VERSION ""

NS_ :

BS_:

BU_: JETSON VCU ACU RES DYN_F DYN_R FSG_DATA_LOGGER MAXON

BO_ 3221225472 VECTOR__INDEPENDENT_SIG_MSG: 0 Vector__XXX
 SG_ EBS_Pressure_Rear : 32|8@1+ (10,0) [0|150] "bar" Vector__XXX
 SG_ EBS_Pressure_Front : 24|8@1+ (10,0) [0|150] "bar" Vector__XXX
 SG_ NewSignal_0005 : 0|8@1+ (1,0) [0|0] "" Vector__XXX
 SG_ NewSignal_0015 : 32|8@1+ (1,0) [0|0] "" Vector__XXX
 SG_ NewSignal_0012 : 56|8@1+ (1,0) [0|0] "" Vector__XXX

BO_ 81 ACU_MS: 1 ACU
 SG_ Mission_Select : 0|8@1+ (1,0) [0|0] ""  JETSON

BO_ 97 JETSON_MS: 1 JETSON
 SG_ Mission_Select : 0|8@1+ (1,0) [0|0] ""  ACU

BO_ 1289 VCU_RPM: 2 VCU
 SG_ rpm_actual : 0|16@1- (1,0) [0|6000] "RPM"  JETSON

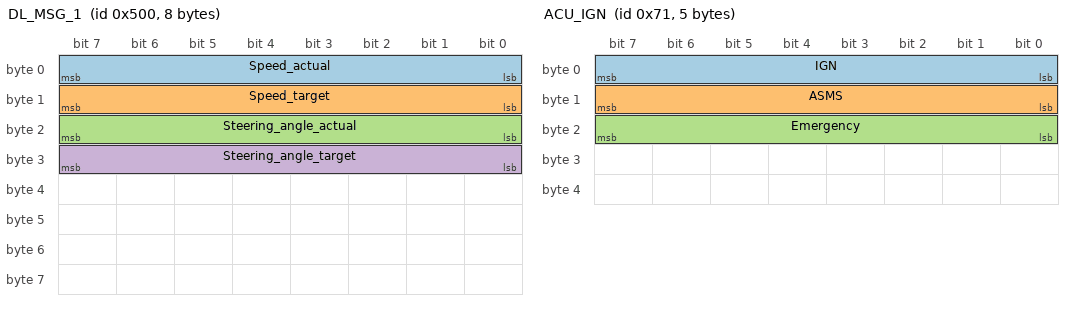
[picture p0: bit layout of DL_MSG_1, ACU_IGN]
BO_ 1280 DL_MSG_1: 8 ACU
 SG_ Speed_actual : 0|8@1+ (0.5,0) [0|0] "Km/h"  VCU
 SG_ Speed_target : 8|8@1+ (0.5,0) [0|0] "Km/h" Vector__XXX
 SG_ Steering_angle_actual : 16|8@1- (0.5,0) [0|0] "º" Vector__XXX
 SG_ Steering_angle_target : 24|8@1- (0.5,0) [0|0] "º" Vector__XXX

BO_ 113 ACU_IGN: 5 ACU
 SG_ IGN : 0|8@1+ (1,0) [0|1] ""  VCU
 SG_ ASMS : 8|8@1+ (1,0) [0|1] ""  VCU
 SG_ Emergency : 16|8@1+ (1,0) [0|0] ""  VCU

BO_ 1299 RD_JETSON: 1 ACU
 SG_ RD : 0|8@1+ (1,0) [0|0] ""  JETSON

BO_ 1283 AS_STATE: 1 JETSON
 SG_ STATE : 0|8@1+ (1,0) [0|0] ""  VCU,ACU

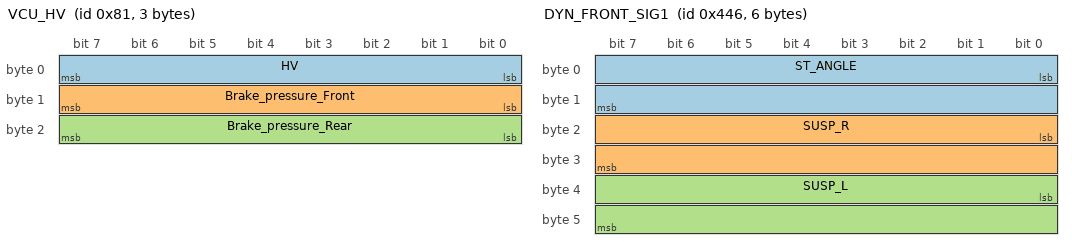
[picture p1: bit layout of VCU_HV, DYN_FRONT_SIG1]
BO_ 129 VCU_HV: 3 VCU
 SG_ HV : 0|8@1+ (1,0) [0|0] ""  ACU
 SG_ Brake_pressure_Front : 8|8@1+ (1,0) [0|0] "" Vector__XXX
 SG_ Brake_pressure_Rear : 16|8@1+ (1,0) [0|0] "" Vector__XXX

BO_ 401 RES: 8 RES
 SG_ SIGNAL : 0|8@1+ (1,0) [0|0] ""  JETSON,ACU

BO_ 1094 DYN_FRONT_SIG1: 6 DYN_F
 SG_ ST_ANGLE : 0|16@1- (0.1,0) [0|0] "º" Vector__XXX
 SG_ SUSP_R : 16|16@1+ (0.1,0) [0|0] "mm" Vector__XXX
 SG_ SUSP_L : 32|16@1+ (0.1,0) [0|0] "mm" Vector__XXX

BO_ 1110 DYN_FRONT_SIG2: 4 DYN_F
 SG_ SPD_LEFT : 0|16@1+ (0.1,0) [0|0] "km/h" Vector__XXX
 SG_ SPD_RIGHT : 16|16@1+ (0.1,0) [0|0] "km/h" Vector__XXX

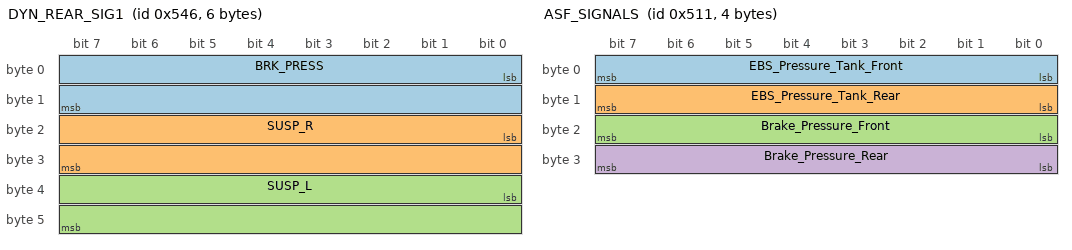
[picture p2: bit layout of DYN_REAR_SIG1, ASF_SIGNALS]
BO_ 1350 DYN_REAR_SIG1: 6 DYN_R
 SG_ BRK_PRESS : 0|16@1+ (0.1,0) [0|0] "bar" Vector__XXX
 SG_ SUSP_R : 16|16@1+ (0.1,0) [0|0] "mm" Vector__XXX
 SG_ SUSP_L : 32|16@1+ (0.1,0) [0|0] "mm" Vector__XXX

BO_ 1366 DYN_REAR_SIG2: 4 DYN_R
 SG_ SPD_LEFT : 0|16@1+ (0.1,0) [0|0] "km/h" Vector__XXX
 SG_ SPD_RIGHT : 16|16@1+ (0.1,0) [0|0] "km/h" Vector__XXX

BO_ 1297 ASF_SIGNALS: 4 ACU
 SG_ EBS_Pressure_Tank_Front : 0|8@1+ (10,0) [0|0] "bar" Vector__XXX
 SG_ EBS_Pressure_Tank_Rear : 8|8@1+ (10,0) [0|0] "bar" Vector__XXX
 SG_ Brake_Pressure_Front : 16|8@1+ (10,0) [0|0] "bar" Vector__XXX
 SG_ Brake_Pressure_Rear : 24|8@1+ (10,0) [0|0] "bar" Vector__XXX

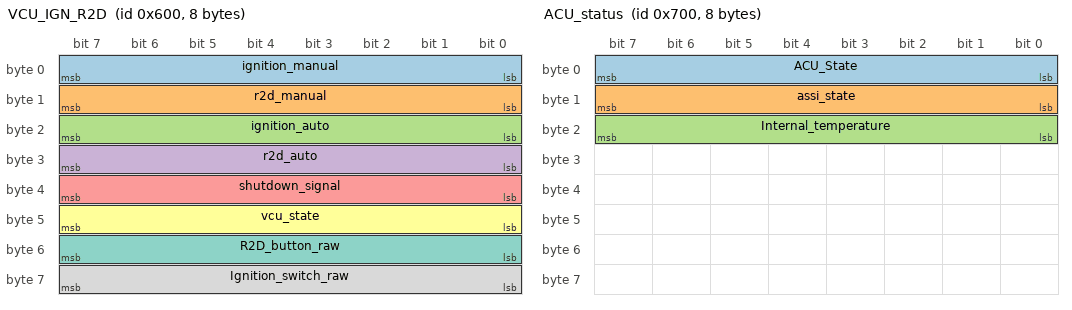
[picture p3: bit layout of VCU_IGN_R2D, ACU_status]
BO_ 1536 VCU_IGN_R2D: 8 VCU
 SG_ ignition_manual : 0|8@1+ (1,0) [0|0] "" Vector__XXX
 SG_ r2d_manual : 8|8@1+ (1,0) [0|0] "" Vector__XXX
 SG_ ignition_auto : 16|8@1+ (1,0) [0|0] "" Vector__XXX
 SG_ r2d_auto : 24|8@1+ (1,0) [0|0] "" Vector__XXX
 SG_ shutdown_signal : 32|8@1+ (1,0) [0|0] "" Vector__XXX
 SG_ vcu_state : 40|8@1+ (1,0) [0|0] "" Vector__XXX
 SG_ R2D_button_raw : 48|8@1+ (1,0) [0|0] "" Vector__XXX
 SG_ Ignition_switch_raw : 56|8@1+ (1,0) [0|0] "" Vector__XXX

BO_ 1792 ACU_status: 8 ACU
 SG_ ACU_State : 0|8@1+ (1,0) [0|0] "" Vector__XXX
 SG_ assi_state : 8|8@1+ (1,0) [0|0] "" Vector__XXX
 SG_ Internal_temperature : 16|8@1+ (1,0) [0|0] "º" Vector__XXX

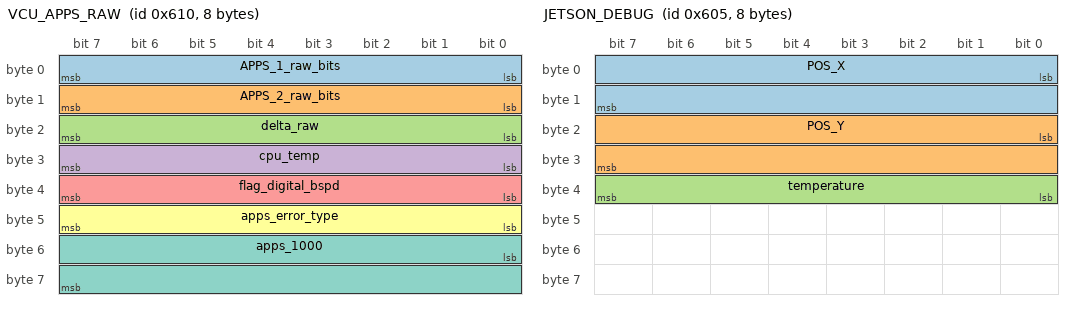
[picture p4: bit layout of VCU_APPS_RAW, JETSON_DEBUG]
BO_ 1552 VCU_APPS_RAW: 8 VCU
 SG_ APPS_1_raw_bits : 0|8@1+ (1,0) [0|0] "" Vector__XXX
 SG_ APPS_2_raw_bits : 8|8@1+ (1,0) [0|0] "" Vector__XXX
 SG_ delta_raw : 16|8@1+ (1,0) [0|0] "" Vector__XXX
 SG_ cpu_temp : 24|8@1+ (1,0) [0|0] "" Vector__XXX
 SG_ flag_digital_bspd : 32|8@1+ (1,0) [0|0] "" Vector__XXX
 SG_ apps_error_type : 40|8@1+ (1,0) [0|0] "" Vector__XXX
 SG_ apps_1000 : 48|16@1+ (1,0) [0|0] "" Vector__XXX

BO_ 1177 RPM_TARGET: 8 JETSON
 SG_ rpm_target : 0|16@1+ (1,0) [0|0] "" Vector__XXX

BO_ 1541 JETSON_DEBUG: 8 JETSON
 SG_ POS_X : 0|16@1+ (0.1,0) [0|0] "m" Vector__XXX
 SG_ POS_Y : 16|16@1+ (0.1,0) [0|0] "m" Vector__XXX
 SG_ temperature : 32|8@1+ (1,0) [0|0] "ºC" Vector__XXX

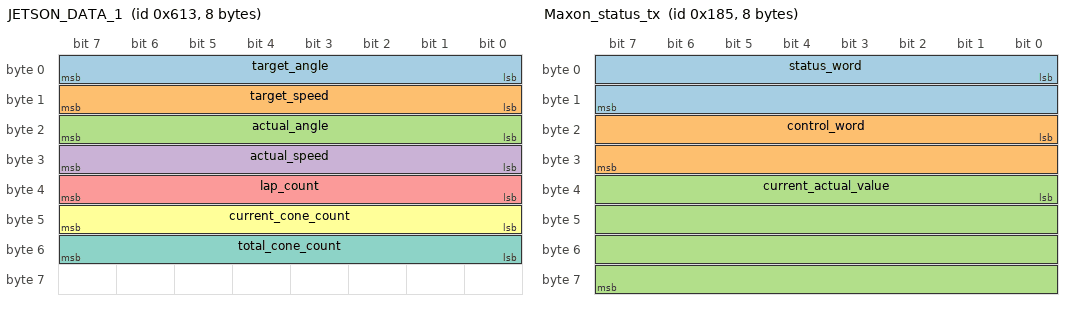
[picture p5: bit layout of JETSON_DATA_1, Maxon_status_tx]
BO_ 1555 JETSON_DATA_1: 8 JETSON
 SG_ target_angle : 0|8@1+ (0.5,0) [0|0] "º" Vector__XXX
 SG_ target_speed : 8|8@1+ (1,0) [0|0] "km/h" Vector__XXX
 SG_ actual_angle : 16|8@1+ (0.5,0) [0|0] "º" Vector__XXX
 SG_ actual_speed : 24|8@1+ (1,0) [0|0] "km/h" Vector__XXX
 SG_ lap_count : 32|8@1+ (1,0) [0|0] "" Vector__XXX
 SG_ current_cone_count : 40|8@1+ (1,0) [0|0] "" Vector__XXX
 SG_ total_cone_count : 48|8@1+ (1,0) [0|0] "" Vector__XXX

BO_ 517 Maxon_mode_rx: 2 MAXON
 SG_ Control_word : 0|8@1+ (1,0) [0|0] "" Vector__XXX

BO_ 1029 Maxon_position_rx: 6 MAXON
 SG_ control_word : 0|8@1+ (1,0) [0|0] "" Vector__XXX
 SG_ target_position : 16|32@1+ (1,0) [0|0] "" Vector__XXX

BO_ 773 Maxon_profile_rx: 8 MAXON
 SG_ profile_velocity : 0|32@1+ (1,0) [0|0] "" Vector__XXX
 SG_ profile_acceleration : 32|32@1+ (1,0) [0|0] "" Vector__XXX

BO_ 389 Maxon_status_tx: 8 MAXON
 SG_ status_word : 0|16@1+ (1,0) [0|0] "" Vector__XXX
 SG_ control_word : 16|16@1+ (1,0) [0|0] "" Vector__XXX
 SG_ current_actual_value : 32|32@1+ (1,0) [0|0] "" Vector__XXX

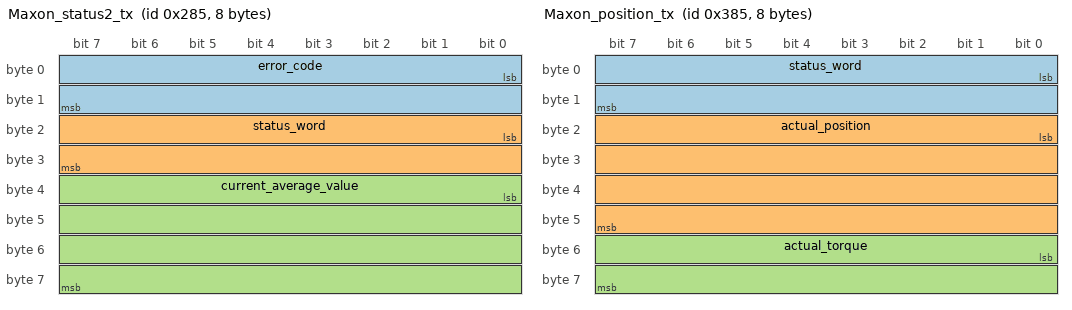
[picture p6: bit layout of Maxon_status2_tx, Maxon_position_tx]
BO_ 645 Maxon_status2_tx: 8 MAXON
 SG_ error_code : 0|16@1+ (1,0) [0|0] "" Vector__XXX
 SG_ status_word : 16|16@1+ (1,0) [0|0] "" Vector__XXX
 SG_ current_average_value : 32|32@1+ (1,0) [0|0] "" Vector__XXX

BO_ 901 Maxon_position_tx: 8 MAXON
 SG_ status_word : 0|16@1+ (1,0) [0|0] "" Vector__XXX
 SG_ actual_position : 16|32@1+ (1,0) [0|0] "" Vector__XXX
 SG_ actual_torque : 48|16@1+ (1,0) [0|0] "" Vector__XXX

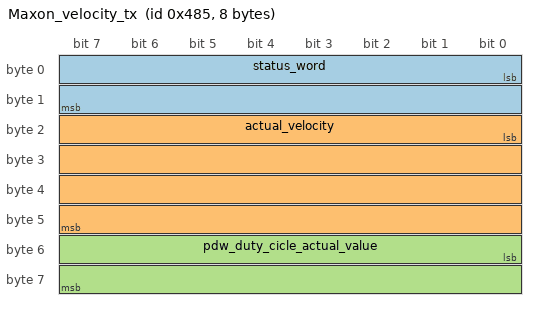
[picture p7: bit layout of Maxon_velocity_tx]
BO_ 1157 Maxon_velocity_tx: 8 MAXON
 SG_ status_word : 0|16@1+ (1,0) [0|0] "" Vector__XXX
 SG_ actual_velocity : 16|32@1+ (1,0) [0|0] "" Vector__XXX
 SG_ pdw_duty_cicle_actual_value : 48|16@1+ (1,0) [0|0] "" Vector__XXX

CM_ SG_ 3221225472 EBS_Pressure_Rear "(null)";
CM_ SG_ 3221225472 EBS_Pressure_Front "Perdu gay";
CM_ SG_ 1289 rpm_actual "valor que a vcu envia para jetson como feedback
";
CM_ SG_ 1299 RD "Envia o estado da acu para a jetson
";
CM_ SG_ 1283 STATE "Regulations";
CM_ SG_ 129 Brake_pressure_Rear "not used, dynamics rear esta a mandar
";
CM_ SG_ 1536 R2D_button_raw "valor do botao raw

";
CM_ SG_ 1536 Ignition_switch_raw "valor do borao raw
";
CM_ SG_ 1177 rpm_target "valor da jetson para a vcu";
CM_ BO_ 1541 "bytes livres para debug
";
VAL_ 81 Mission_Select 0 "Manual" 1 "Acceleration" 2 "Skidpad" 3 "Trackdrive" 4 "Braketest" 5 "Inspection" 6 "Autocross" ;
VAL_ 97 Mission_Select 0 "Manual" 1 "Acceleration" 2 "Skidpadd" 3 "Trackdrive" 4 "Braketest" 5 "Inspection" 6 "Autocross" ;
VAL_ 113 IGN 0 "OFF" 1 "ON" ;
VAL_ 113 ASMS 0 "OFF" 1 "ON" ;
VAL_ 113 Emergency 1 "Emergency_ON" 0 "Emergency_OFF" ;
VAL_ 1299 RD 0 "OFF" 1 "ON" ;
VAL_ 1283 STATE 1 "OFF" 2 "Ready" 3 "Driving" 4 "Emergency" 5 "Finish" ;
VAL_ 129 HV 0 "hv off" 9 "hv on" 10 "contactor error" ;
VAL_ 401 SIGNAL 5 "GO_SIGNAL" 7 "GO_SIGNAL_2" 0 "EMERGENCY" ;
VAL_ 1536 vcu_state 1 "INIT" 2 "SHUTDOWN" 3 "STANDBY" 4 "PRECHARGE" 5 "WAIT_R2D_MANUAL" 6 "WAIT_R2D_AUTO" 7 "READY_MANUAL" 8 "READY_AUTO" 9 "EMERGENCY" ;
VAL_ 1792 ACU_State 0 "INIT" 1 "MS" 2 "JETSON_WAITING" 3 "IBIT_SEQ" 4 "READY" 5 "DRIVING" 6 "EBS_EROR" 7 "EMERGENCY" 8 "FINISHED" 9 "MANUAL" ;
VAL_ 517 Control_word 6 "shutdown" 15 "new_position_bit" ;
VAL_ 1029 control_word 31 "absolute_position" 63 "absolute_position_immediatly" 127 "relative position_immediatly" 95 "relative_position" ;
